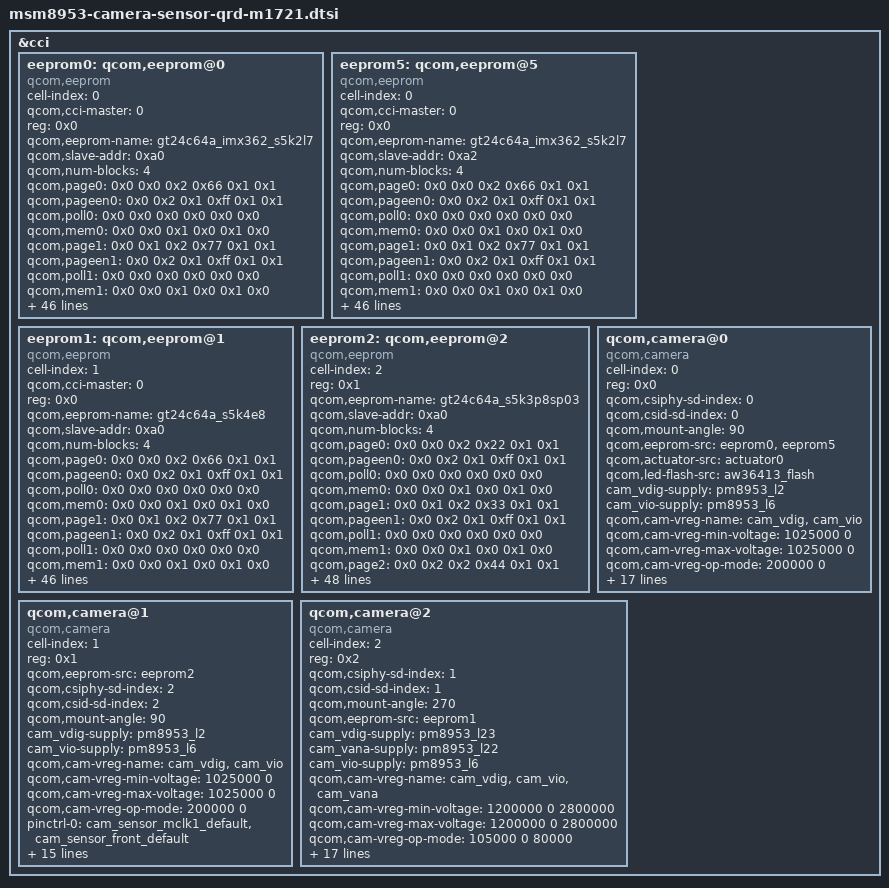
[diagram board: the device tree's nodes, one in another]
/*
 * Copyright (c) 2017, The Linux Foundation. All rights reserved.
 *
 * This program is free software; you can redistribute it and/or modify
 * it under the terms of the GNU General Public License version 2 and
 * only version 2 as published by the Free Software Foundation.
 *
 * This program is distributed in the hope that it will be useful,
 * but WITHOUT ANY WARRANTY; without even the implied warranty of
 * MERCHANTABILITY or FITNESS FOR A PARTICULAR PURPOSE.  See the
 * GNU General Public License for more details.
 */

&cci {
	eeprom0: qcom,eeprom@0 {
        cell-index = <0>;
        compatible = "qcom,eeprom";
        qcom,cci-master = <0>;
        reg = <0x0>;
        qcom,eeprom-name = "gt24c64a_imx362_s5k2l7";
        qcom,slave-addr = <0xa0>;
        qcom,num-blocks = <4>;
        qcom,page0 = <0x0 0x0 0x2 0x66 0x1 0x1>;
        qcom,pageen0 = <0x0 0x2 0x1 0xff 0x1 0x1>;
        qcom,poll0 = <0x0 0x0 0x0 0x0 0x0 0x0>;
        qcom,mem0 = <0x0 0x0 0x1 0x0 0x1 0x0>;
        qcom,page1 = <0x0 0x1 0x2 0x77 0x1 0x1>;
        qcom,pageen1 = <0x0 0x2 0x1 0xff 0x1 0x1>;
        qcom,poll1 = <0x0 0x0 0x0 0x0 0x0 0x0>;
        qcom,mem1 = <0x0 0x0 0x1 0x0 0x1 0x0>;
        qcom,page2 = <0x0 0x2 0x2 0x88 0x1 0x1>;
        qcom,pageen2 = <0x0 0x2 0x1 0xff 0x1 0x1>;
        qcom,poll2 = <0x0 0x0 0x0 0x0 0x0 0x0>;
        qcom,mem2 = <0x0 0x0 0x1 0x0 0x1 0x0>;
        qcom,page3 = <0x0 0x0 0x1 0x55 0x1 0x1>;
        qcom,pageen3 = <0x0 0x2 0x1 0xff 0x1 0x1>;
        qcom,poll3 = <0x0 0x0 0x2 0x0 0x1 0x1>;
        qcom,mem3 = <0x135a 0x0 0x2 0x0 0x1 0x0>;
        qcom,saddr4 = <0xaa>;
        qcom,page4 = <0x0 0x0 0x1 0x99 0x1 0x1>;
        qcom,pageen4 = <0x0 0x2 0x1 0xff 0x1 0x1>;
        qcom,poll4 = <0x0 0x0 0x0 0x0 0x0 0x0>;
        qcom,mem4 = <0xff 0x0 0x1 0x0 0x1 0x0>;
        qcom,saddr5 = <0xac>;
        qcom,page5 = <0x0 0x0 0x1 0x11 0x1 0x1>;
        qcom,pageen5 = <0x0 0x2 0x1 0xff 0x1 0x1>;
        qcom,poll5 = <0x0 0x0 0x0 0x0 0x0 0x0>;
        qcom,mem5 = <0x55 0x0 0x1 0x0 0x1 0x0>;
        cam_vdig-supply = <&pm8953_l2>;
        cam_vio-supply = <&pm8953_l6>;
        qcom,cam-vreg-name = "cam_vdig", "cam_vio";
        qcom,cam-vreg-min-voltage = <1025000 0>;
        qcom,cam-vreg-max-voltage = <1025000 0>;
        qcom,cam-vreg-op-mode = <200000 0>;
        pinctrl-names = "cam_default", "cam_suspend";
        pinctrl-0 = <&cam_sensor_mclk0_default &cam_sensor_rear_default>;
        pinctrl-1 = <&cam_sensor_mclk0_sleep &cam_sensor_rear_sleep>;
        gpios = <&tlmm 26 0x0>, 
                <&tlmm 40 0x0>, 
                <&tlmm 17 0x0>;
        qcom,gpio-reset = <1>;
        qcom,gpio-vana = <2>;
        /delete-property/ qcom,gpio-standby;
        qcom,gpio-req-tbl-num = <0 1 2>;
        qcom,gpio-req-tbl-flags = <1 0 0>;
        qcom,gpio-req-tbl-label = 
            "CAMIF_MCLK0", 
            "CAM_RESET0", 
            "CAM_GPIO_VANA0";
        qcom,cam-power-seq-type = 
            "sensor_gpio", 
            "sensor_gpio", 
            "sensor_vreg", 
            "sensor_vreg", 
            "sensor_gpio", 
            "sensor_clk";
        qcom,cam-power-seq-val = 
            "sensor_gpio_reset", 
            "sensor_gpio_vana", 
            "cam_vdig", 
            "cam_vio", 
            "sensor_gpio_reset", 
            "sensor_cam_mclk";
        qcom,cam-power-seq-cfg-val = <0 1 1 1 1 24000000>;
        qcom,cam-power-seq-delay = <10 10 10 10 10 5>;
        status = "ok";
        clocks = <&clock_gcc clk_mclk0_clk_src>,
				<&clock_gcc clk_gcc_camss_mclk0_clk>;
        clock-names = "cam_src_clk", "cam_clk";
        qcom,clock-rates = <24000000 0>;
    };

    eeprom5: qcom,eeprom@5 {
        cell-index = <0>;
        compatible = "qcom,eeprom";
        qcom,cci-master = <0>;
        reg = <0x0>;
        qcom,eeprom-name = "gt24c64a_imx362_s5k2l7";
        qcom,slave-addr = <0xa2>;
        qcom,num-blocks = <4>;
        qcom,page0 = <0x0 0x0 0x2 0x66 0x1 0x1>;
        qcom,pageen0 = <0x0 0x2 0x1 0xff 0x1 0x1>;
        qcom,poll0 = <0x0 0x0 0x0 0x0 0x0 0x0>;
        qcom,mem0 = <0x0 0x0 0x1 0x0 0x1 0x0>;
        qcom,page1 = <0x0 0x1 0x2 0x77 0x1 0x1>;
        qcom,pageen1 = <0x0 0x2 0x1 0xff 0x1 0x1>;
        qcom,poll1 = <0x0 0x0 0x0 0x0 0x0 0x0>;
        qcom,mem1 = <0x0 0x0 0x1 0x0 0x1 0x0>;
        qcom,page2 = <0x0 0x2 0x2 0x88 0x1 0x1>;
        qcom,pageen2 = <0x0 0x2 0x1 0xff 0x1 0x1>;
        qcom,poll2 = <0x0 0x0 0x0 0x0 0x0 0x0>;
        qcom,mem2 = <0x0 0x0 0x1 0x0 0x1 0x0>;
        qcom,page3 = <0x0 0x0 0x1 0x55 0x1 0x1>;
        qcom,pageen3 = <0x0 0x2 0x1 0xff 0x1 0x1>;
        qcom,poll3 = <0x0 0x0 0x2 0x0 0x1 0x1>;
        qcom,mem3 = <0x1d90 0x0 0x2 0x0 0x1 0x0>;
        qcom,saddr4 = <0xaa>;
        qcom,page4 = <0x0 0x0 0x1 0x99 0x1 0x1>;
        qcom,pageen4 = <0x0 0x2 0x1 0xff 0x1 0x1>;
        qcom,poll4 = <0x0 0x0 0x0 0x0 0x0 0x0>;
        qcom,mem4 = <0xff 0x0 0x1 0x0 0x1 0x0>;
        qcom,saddr5 = <0xac>;
        qcom,page5 = <0x0 0x0 0x1 0x11 0x1 0x1>;
        qcom,pageen5 = <0x0 0x2 0x1 0xff 0x1 0x1>;
        qcom,poll5 = <0x0 0x0 0x0 0x0 0x0 0x0>;
        qcom,mem5 = <0x55 0x0 0x1 0x0 0x1 0x0>;
        cam_vdig-supply = <&pm8953_l2>;
        cam_vio-supply = <&pm8953_l6>;
        qcom,cam-vreg-name = "cam_vdig", "cam_vio";
        qcom,cam-vreg-min-voltage = <1025000 0>;
        qcom,cam-vreg-max-voltage = <1025000 0>;
        qcom,cam-vreg-op-mode = <200000 0>;
        pinctrl-names = "cam_default", "cam_suspend";
        pinctrl-0 = <&cam_sensor_mclk0_default &cam_sensor_rear_default>;
        pinctrl-1 = <&cam_sensor_mclk0_sleep &cam_sensor_rear_sleep>;
        gpios = <&tlmm 26 0>, 
                <&tlmm 40 0>, 
                <&tlmm 17 0>;
        qcom,gpio-reset = <1>;
        qcom,gpio-vana = <2>;
        qcom,gpio-req-tbl-num = <0 1 2>;
        qcom,gpio-req-tbl-flags = <1 0 0>;
        qcom,gpio-req-tbl-label = 
            "CAMIF_MCLK0", 
            "CAM_RESET0", 
            "CAM_GPIO_VANA0";
        qcom,cam-power-seq-type = 
            "sensor_gpio", 
            "sensor_gpio", 
            "sensor_vreg", 
            "sensor_vreg", 
            "sensor_gpio", 
            "sensor_clk";
        qcom,cam-power-seq-val = 
            "sensor_gpio_reset", 
            "sensor_gpio_vana", 
            "cam_vdig", 
            "cam_vio", 
            "sensor_gpio_reset", 
            "sensor_cam_mclk";
        qcom,cam-power-seq-cfg-val = <0 1 1 1 1 24000000>;
        qcom,cam-power-seq-delay = <10 10 10 10 10 5>;
        status = "ok";
        clocks = <&clock_gcc clk_mclk0_clk_src>,
				<&clock_gcc clk_gcc_camss_mclk0_clk>;
        clock-names = "cam_src_clk", "cam_clk";
        qcom,clock-rates = <24000000 0>;
    };

    eeprom1: qcom,eeprom@1 {
        cell-index = <1>;
        compatible = "qcom,eeprom";
        qcom,cci-master = <0>;
        reg = <0x0>;
        qcom,eeprom-name = "gt24c64a_s5k4e8";
        qcom,slave-addr = <0xa0>;
        qcom,num-blocks = <4>;
        qcom,page0 = <0x0 0x0 0x2 0x66 0x1 0x1>;
        qcom,pageen0 = <0x0 0x2 0x1 0xff 0x1 0x1>;
        qcom,poll0 = <0x0 0x0 0x0 0x0 0x0 0x0>;
        qcom,mem0 = <0x0 0x0 0x1 0x0 0x1 0x0>;
        qcom,page1 = <0x0 0x1 0x2 0x77 0x1 0x1>;
        qcom,pageen1 = <0x0 0x2 0x1 0xff 0x1 0x1>;
        qcom,poll1 = <0x0 0x0 0x0 0x0 0x0 0x0>;
        qcom,mem1 = <0x0 0x0 0x1 0x0 0x1 0x0>;
        qcom,page2 = <0x0 0x2 0x2 0x88 0x1 0x1>;
        qcom,pageen2 = <0x0 0x2 0x1 0xff 0x1 0x1>;
        qcom,poll2 = <0x0 0x0 0x0 0x0 0x0 0x0>;
        qcom,mem2 = <0x0 0x0 0x1 0x0 0x1 0x0>;
        qcom,page3 = <0x0 0x0 0x1 0x55 0x1 0x1>;
        qcom,pageen3 = <0x0 0x2 0x1 0xff 0x1 0x1>;
        qcom,poll3 = <0x0 0x0 0x2 0x0 0x1 0x1>;
        qcom,mem3 = <0x1a6c 0x0 0x2 0x0 0x1 0x0>;
        qcom,saddr4 = <0xaa>;
        qcom,page4 = <0x0 0x0 0x1 0x99 0x1 0x1>;
        qcom,pageen4 = <0x0 0x2 0x1 0xff 0x1 0x1>;
        qcom,poll4 = <0x0 0x0 0x0 0x0 0x0 0x0>;
        qcom,mem4 = <0xff 0x0 0x1 0x0 0x1 0x0>;
        qcom,saddr5 = <0xac>;
        qcom,page5 = <0x0 0x0 0x1 0x11 0x1 0x1>;
        qcom,pageen5 = <0x0 0x2 0x1 0xff 0x1 0x1>;
        qcom,poll5 = <0x0 0x0 0x0 0x0 0x0 0x0>;
        qcom,mem5 = <0x55 0x0 0x1 0x0 0x1 0x0>;
        cam_vdig-supply = <&pm8953_l2>;
        cam_vio-supply = <&pm8953_l6>;
        qcom,cam-vreg-name = "cam_vdig", "cam_vio";
        qcom,cam-vreg-min-voltage = <1025000 0>;
        qcom,cam-vreg-max-voltage = <1025000 0>;
        qcom,cam-vreg-op-mode = <200000 0>;
        pinctrl-names = "cam_default", "cam_suspend";
        pinctrl-0 = <&cam_sensor_mclk0_default &cam_sensor_rear_default>;
        pinctrl-1 = <&cam_sensor_mclk0_sleep &cam_sensor_rear_sleep>;
        gpios = <&tlmm 26 0>, 
                <&tlmm 40 0>, 
                <&tlmm 17 0>;
        qcom,gpio-reset = <1>;
        qcom,gpio-vana = <2>;
        qcom,gpio-req-tbl-num = <0 1 2>;
        qcom,gpio-req-tbl-flags = <1 0 0>;
        qcom,gpio-req-tbl-label = 
            "CAMIF_MCLK0", 
            "CAM_RESET0", 
            "CAM_GPIO_VANA0";
        qcom,cam-power-seq-type = 
            "sensor_gpio", 
            "sensor_gpio", 
            "sensor_vreg", 
            "sensor_vreg", 
            "sensor_gpio", 
            "sensor_clk";
        qcom,cam-power-seq-val = 
            "sensor_gpio_reset", 
            "sensor_gpio_vana", 
            "cam_vdig", 
            "cam_vio", 
            "sensor_gpio_reset", 
            "sensor_cam_mclk";
        qcom,cam-power-seq-cfg-val = <0 1 1 1 1 24000000>;
        qcom,cam-power-seq-delay = <10 10 10 10 10 5>;
        status = "ok";
        clocks = <&clock_gcc clk_mclk0_clk_src>,
				<&clock_gcc clk_gcc_camss_mclk0_clk>;
        clock-names = "cam_src_clk", "cam_clk";
        qcom,clock-rates = <24000000 0>;
    };

    eeprom2: qcom,eeprom@2 {
        cell-index = <2>;
        reg = <0x1>;
        compatible = "qcom,eeprom";
        qcom,eeprom-name = "gt24c64a_s5k3p8sp03";
        qcom,slave-addr = <0xa0>;
        qcom,num-blocks = <4>;
        qcom,page0 = <0x0 0x0 0x2 0x22 0x1 0x1>;
        qcom,pageen0 = <0x0 0x2 0x1 0xff 0x1 0x1>;
        qcom,poll0 = <0x0 0x0 0x0 0x0 0x0 0x0>;
        qcom,mem0 = <0x0 0x0 0x1 0x0 0x1 0x0>;
        qcom,page1 = <0x0 0x1 0x2 0x33 0x1 0x1>;
        qcom,pageen1 = <0x0 0x2 0x1 0xff 0x1 0x1>;
        qcom,poll1 = <0x0 0x0 0x0 0x0 0x0 0x0>;
        qcom,mem1 = <0x0 0x0 0x1 0x0 0x1 0x0>;
        qcom,page2 = <0x0 0x2 0x2 0x44 0x1 0x1>;
        qcom,pageen2 = <0x0 0x2 0x1 0xff 0x1 0x1>;
        qcom,poll2 = <0x0 0x0 0x0 0x0 0x0 0x0>;
        qcom,mem2 = <0x0 0x0 0x1 0x0 0x1 0x0>;
        qcom,page3 = <0x0 0x0 0x1 0x55 0x1 0x1>;
        qcom,pageen3 = <0x0 0x2 0x1 0xff 0x1 0x1>;
        qcom,poll3 = <0x0 0x0 0x2 0x0 0x1 0x1>;
        qcom,mem3 = <0xf40 0x0 0x2 0x0 0x1 0x0>;
        qcom,saddr4 = <0xaa>;
        qcom,page4 = <0x0 0x0 0x1 0x99 0x1 0x1>;
        qcom,pageen4 = <0x0 0x2 0x1 0xff 0x1 0x1>;
        qcom,poll4 = <0x0 0x0 0x0 0x0 0x0 0x0>;
        qcom,mem4 = <0xff 0x0 0x1 0x0 0x1 0x0>;
        qcom,saddr5 = <0xac>;
        qcom,page5 = <0x0 0x0 0x1 0x11 0x1 0x1>;
        qcom,pageen5 = <0x0 0x2 0x1 0xff 0x1 0x1>;
        qcom,poll5 = <0x0 0x0 0x0 0x0 0x0 0x0>;
        qcom,mem5 = <0x55 0x0 0x1 0x0 0x1 0x0>;
        cam_vdig-supply = <&pm8953_l2>;
        cam_vio-supply = <&pm8953_l6>;
        qcom,cam-vreg-name = "cam_vdig", "cam_vio";
        qcom,cam-vreg-min-voltage = <1025000 0>;
        qcom,cam-vreg-max-voltage = <1025000 0>;
        qcom,cam-vreg-op-mode = <200000 0>;
        pinctrl-names = "cam_default", "cam_suspend";
        pinctrl-0 = <&cam_sensor_mclk1_default &cam_sensor_front_default>;
        pinctrl-1 = <&cam_sensor_mclk1_sleep &cam_sensor_front_sleep>;
        gpios = <&tlmm 27  0>,
                <&tlmm 129 0>, 
                <&tlmm 36  0>;
        qcom,gpio-reset = <1>;
        qcom,gpio-vana = <2>;
        /delete-property/ qcom,gpio-standby;
        qcom,gpio-req-tbl-num = <0 1 2>;
        qcom,gpio-req-tbl-flags = <1 0 0>;
        qcom,gpio-req-tbl-label = 
            "CAMIF_MCLK1", 
            "CAM_RESET1", 
            "CAM_GPIO_VANA1";
        qcom,sensor-position = <4>;
        qcom,sensor-mode = <0>;
        qcom,cci-master = <1>;
        qcom,cam-power-seq-type = 
            "sensor_gpio", 
            "sensor_gpio", 
            "sensor_vreg", 
            "sensor_vreg", 
            "sensor_gpio", 
            "sensor_clk";
        qcom,cam-power-seq-val = 
            "sensor_gpio_reset", 
            "sensor_gpio_vana", 
            "cam_vio", 
            "cam_vdig", 
            "sensor_gpio_reset", 
            "sensor_cam_mclk";
        qcom,cam-power-seq-cfg-val = <0 1 1 1 1 24000000>;
        qcom,cam-power-seq-delay = <10 10 10 10 10 5>;
        status = "ok";
        clocks = <&clock_gcc clk_mclk1_clk_src>,
				<&clock_gcc clk_gcc_camss_mclk1_clk>;
        clock-names = "cam_src_clk", "cam_clk";
        qcom,clock-rates = <24000000 0>;
    };

    qcom,camera@0 {
        cell-index = <0>;
        compatible = "qcom,camera";
        reg = <0x0>;
        qcom,csiphy-sd-index = <0>;
        qcom,csid-sd-index = <0>;
        qcom,mount-angle = <90>;
        qcom,eeprom-src = <&eeprom0 &eeprom5>;
        qcom,actuator-src = <&actuator0>;
        qcom,led-flash-src = <&aw36413_flash>;
        cam_vdig-supply = <&pm8953_l2>;
        cam_vio-supply = <&pm8953_l6>;
        qcom,cam-vreg-name = 
            "cam_vdig", 
            "cam_vio";
        qcom,cam-vreg-min-voltage = <1025000 0>;
        qcom,cam-vreg-max-voltage = <1025000 0>;
        qcom,cam-vreg-op-mode = <200000 0>;
        pinctrl-names = 
            "cam_default", 
            "cam_suspend";
        pinctrl-0 = <&cam_sensor_mclk0_default &cam_sensor_rear_default>;
        pinctrl-1 = <&cam_sensor_mclk0_sleep &cam_sensor_rear_sleep>;
        gpios = <&tlmm 26 0>, 
                <&tlmm 40 0>, 
                <&tlmm 17 0>;
        qcom,gpio-reset = <1>;
        qcom,gpio-vana = <2>;
        /delete-property/ qcom,gpio-standby;
        qcom,gpio-req-tbl-num = <0 1 2>;
        qcom,gpio-req-tbl-flags = <1 0 0>;
        qcom,gpio-req-tbl-label = 
            "CAMIF_MCLK0", 
            "CAM_RESET0", 
            "CAM_GPIO_VANA0";
        qcom,sensor-position = <0>;
        qcom,sensor-mode = <0>;
        qcom,cci-master = <0>;
        status = "ok";
        clocks = <&clock_gcc clk_mclk0_clk_src>,
				<&clock_gcc clk_gcc_camss_mclk0_clk>;
        clock-names = "cam_src_clk", "cam_clk";
        qcom,clock-rates = <24000000 0>;
    };

    qcom,camera@1 {
        cell-index = <1>;
        compatible = "qcom,camera";
        reg = <0x1>;
        qcom,eeprom-src = <&eeprom2>;
        qcom,csiphy-sd-index = <2>;
        qcom,csid-sd-index = <2>;
        qcom,mount-angle = <90>;
        cam_vdig-supply = <&pm8953_l2>;
        cam_vio-supply = <&pm8953_l6>;
        qcom,cam-vreg-name = 
            "cam_vdig", 
            "cam_vio";
        qcom,cam-vreg-min-voltage = <1025000 0>;
        qcom,cam-vreg-max-voltage = <1025000 0>;
        qcom,cam-vreg-op-mode = <200000 0>;
        pinctrl-names = 
            "cam_default", 
            "cam_suspend";
        pinctrl-0 = <&cam_sensor_mclk1_default &cam_sensor_front_default>;
        pinctrl-1 = <&cam_sensor_mclk1_sleep &cam_sensor_front_sleep>;
        gpios = <&tlmm 27  0>, 
                <&tlmm 129 0>, 
                <&tlmm 36  0>;
        /delete-property/ qcom,gpio-standby;
        qcom,gpio-reset = <1>;
        qcom,gpio-vana = <2>;
        qcom,gpio-req-tbl-num = <0 1 2>;
        qcom,gpio-req-tbl-flags = <1 0 0>;
        qcom,gpio-req-tbl-label = 
            "CAMIF_MCLK1", 
            "CAM_RESET1", 
            "CAM_GPIO_VANA1";
        qcom,sensor-position = <4>;
        qcom,sensor-mode = <0>;
        qcom,cci-master = <1>;
        status = "ok";
        clocks = <&clock_gcc clk_mclk1_clk_src>,
				<&clock_gcc clk_gcc_camss_mclk1_clk>;
        clock-names = "cam_src_clk", "cam_clk";
        qcom,clock-rates = <24000000 0>;
    };

    qcom,camera@2 {
        cell-index = <2>;
        compatible = "qcom,camera";
        reg = <0x2>;
        qcom,csiphy-sd-index = <1>;
        qcom,csid-sd-index = <1>;
        qcom,mount-angle = <270>;
        qcom,eeprom-src = <&eeprom1>;
        cam_vdig-supply = <&pm8953_l23>;
        cam_vana-supply = <&pm8953_l22>;
        cam_vio-supply = <&pm8953_l6>;
        qcom,cam-vreg-name = 
            "cam_vdig", 
            "cam_vio", 
            "cam_vana";
        qcom,cam-vreg-min-voltage = <1200000 0 2800000>;
        qcom,cam-vreg-max-voltage = <1200000 0 2800000>;
        qcom,cam-vreg-op-mode = <105000 0 80000>;
        qcom,gpio-no-mux = <0>;
        pinctrl-names = 
            "cam_default", 
            "cam_suspend";
        pinctrl-0 = <&cam_sensor_mclk2_default &cam_sensor_front1_default>;
        pinctrl-1 = <&cam_sensor_mclk2_sleep &cam_sensor_front1_sleep>;
        gpios = <&tlmm 28 0>, 
                <&tlmm 131 0>;
        /delete-property/ qcom,gpio-standby;
        qcom,gpio-reset = <1>;
        qcom,gpio-req-tbl-num = <0 1>;
        qcom,gpio-req-tbl-flags = <1 0>;
        qcom,gpio-req-tbl-label = 
            "CAMIF_MCLK2", 
            "CAM_RESET2";
        qcom,sensor-position = <2>;
        qcom,sensor-mode = <0>;
        qcom,cci-master = <1>;
        status = "ok";
        clocks = <&clock_gcc clk_mclk2_clk_src>,
				<&clock_gcc clk_gcc_camss_mclk2_clk>;
        clock-names = "cam_src_clk", "cam_clk";
        qcom,clock-rates = <24000000 0>;
    };
};
